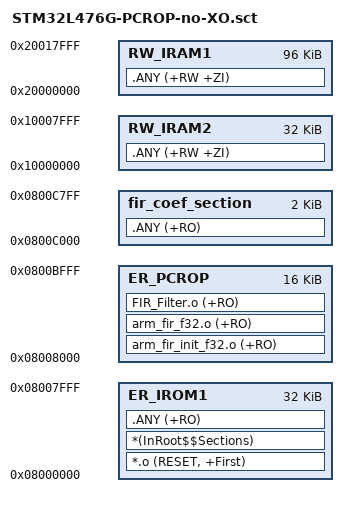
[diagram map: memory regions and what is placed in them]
; *************************************************************
; *** Scatter-Loading Description File generated by uVision ***
; *************************************************************

LR_IROM1 0x08000000 0x00008000  {    ; load region size_region
  ER_IROM1 0x08000000 0x00008000  {  ; load address = execution address
   *.o (RESET, +First)
   *(InRoot$$Sections)
   .ANY (+RO)
  }
  
  RW_IRAM1 0x20000000 0x00018000  {  ; RW data
   .ANY (+RW +ZI)
  }
  RW_IRAM2 0x10000000 0x00008000  {
   .ANY (+RW +ZI)
  }
}

LR_PCROP 0x08008000 0x00004000  {
  ER_PCROP 0x08008000 0x00004000  {  ; load address = execution address
	arm_fir_init_f32.o (+RO)
	arm_fir_f32.o (+RO)
	FIR_Filter.o (+RO)	
  }
}
; Define a section of 2KB for FIR coefficients
; This section correspond to Flash page number = 24
LR_DATA 0x0800C000 0x00000800  {
  fir_coef_section 0x0800C000 0x00000800  {  
	.ANY (+RO)	
  }
}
